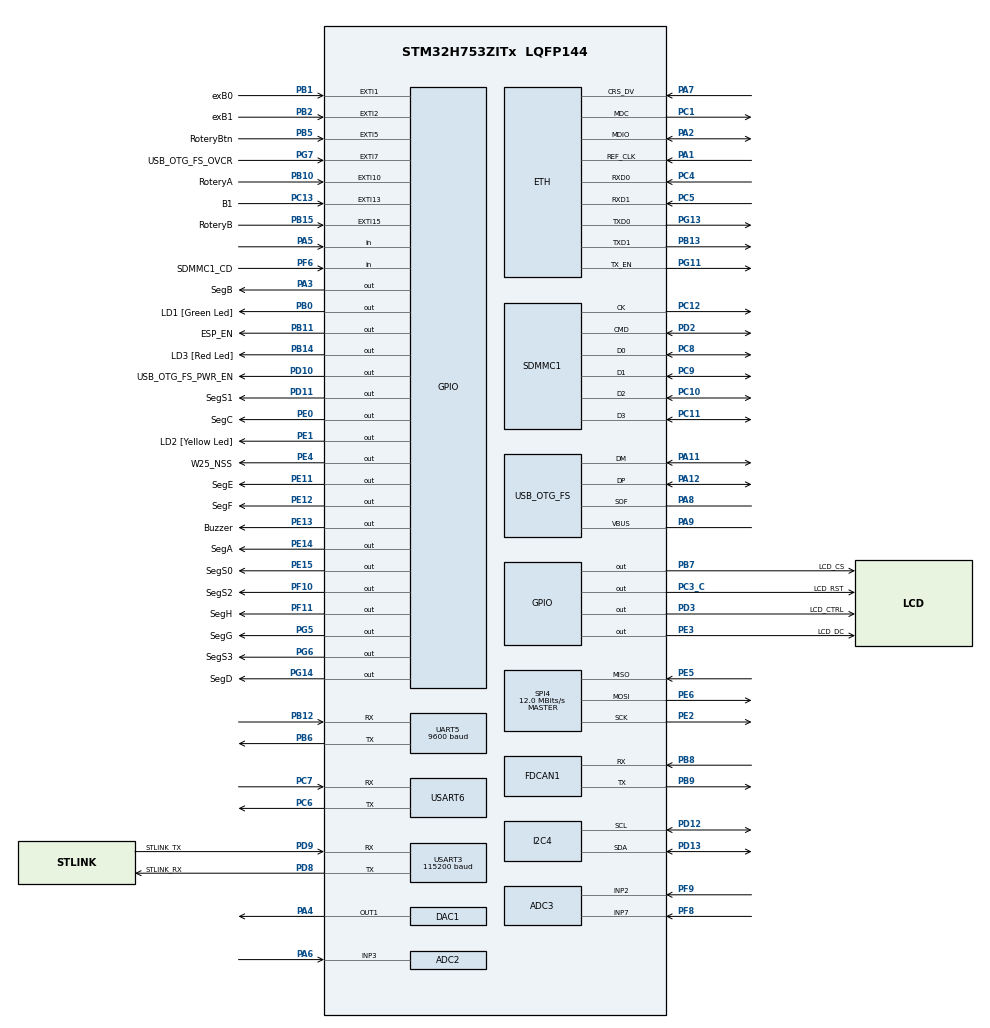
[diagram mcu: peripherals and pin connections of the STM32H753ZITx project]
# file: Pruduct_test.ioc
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ADC2.Channel-0\#ChannelRegularConversion=ADC_CHANNEL_3
ADC2.ClockPrescaler=ADC_CLOCK_ASYNC_DIV4
ADC2.ExternalTrigConv=ADC_EXTERNALTRIG_T15_TRGO
ADC2.NbrOfConversionFlag=1
ADC2.OffsetNumber-0\#ChannelRegularConversion=ADC_OFFSET_NONE
ADC2.OffsetSignedSaturation-0\#ChannelRegularConversion=DISABLE
ADC2.Rank-0\#ChannelRegularConversion=1
ADC2.SamplingTime-0\#ChannelRegularConversion=ADC_SAMPLETIME_387CYCLES_5
ADC3.Channel-0\#ChannelRegularConversion=ADC_CHANNEL_2
ADC3.NbrOfConversionFlag=1
ADC3.OffsetNumber-0\#ChannelRegularConversion=ADC_OFFSET_NONE
ADC3.OffsetSignedSaturation-0\#ChannelRegularConversion=DISABLE
ADC3.Rank-0\#ChannelRegularConversion=1
ADC3.SamplingTime-0\#ChannelRegularConversion=ADC_SAMPLETIME_1CYCLE_5
CORTEX_M7.AccessPermission-Cortex_Memory_Protection_Unit_Region1_Settings=MPU_REGION_FULL_ACCESS
CORTEX_M7.AccessPermission_S-Cortex_Memory_Protection_Unit_Region1_Settings_S=MPU_REGION_FULL_ACCESS
CORTEX_M7.AccessPermission_Spec=MPU_REGION_FULL_ACCESS
CORTEX_M7.BaseAddress-Cortex_Memory_Protection_Unit_Region0_Settings=0x0
CORTEX_M7.BaseAddress-Cortex_Memory_Protection_Unit_Region1_Settings=0x030020000
CORTEX_M7.BaseAddress-Cortex_Memory_Protection_Unit_Region2_Settings=0x30040000
CORTEX_M7.BaseAddress_S-Cortex_Memory_Protection_Unit_Region1_Settings_S=0x30040000
CORTEX_M7.BaseAddress_Spec=0x30020000
CORTEX_M7.CPU_DCache=Enabled
CORTEX_M7.CPU_ICache=Enabled
CORTEX_M7.DisableExec-Cortex_Memory_Protection_Unit_Region0_Settings=MPU_INSTRUCTION_ACCESS_DISABLE
CORTEX_M7.DisableExec_S-Cortex_Memory_Protection_Unit_Region1_Settings_S=MPU_INSTRUCTION_ACCESS_DISABLE
CORTEX_M7.DisableExec_Spec=MPU_INSTRUCTION_ACCESS_DISABLE
CORTEX_M7.Enable-Cortex_Memory_Protection_Unit_Region0_Settings=MPU_REGION_ENABLE
CORTEX_M7.Enable-Cortex_Memory_Protection_Unit_Region1_Settings=MPU_REGION_ENABLE
CORTEX_M7.Enable-Cortex_Memory_Protection_Unit_Region2_Settings=MPU_REGION_ENABLE
CORTEX_M7.Enable_S-Cortex_Memory_Protection_Unit_Region1_Settings_S=MPU_REGION_ENABLE
CORTEX_M7.Enable_S-Cortex_Memory_Protection_Unit_Region2_Settings_S=__NULL
CORTEX_M7.Enable_Spec=MPU_REGION_ENABLE
CORTEX_M7.IsBufferable-Cortex_Memory_Protection_Unit_Region0_Settings=MPU_ACCESS_NOT_BUFFERABLE
CORTEX_M7.IsBufferable-Cortex_Memory_Protection_Unit_Region1_Settings=MPU_ACCESS_BUFFERABLE
CORTEX_M7.IsBufferable-Cortex_Memory_Protection_Unit_Region2_Settings=MPU_ACCESS_BUFFERABLE
CORTEX_M7.IsBufferable_S-Cortex_Memory_Protection_Unit_Region1_Settings_S=MPU_ACCESS_BUFFERABLE
CORTEX_M7.IsBufferable_Spec=MPU_ACCESS_NOT_BUFFERABLE
CORTEX_M7.IsCacheable-Cortex_Memory_Protection_Unit_Region0_Settings=MPU_ACCESS_CACHEABLE
CORTEX_M7.IsCacheable-Cortex_Memory_Protection_Unit_Region1_Settings=MPU_ACCESS_CACHEABLE
CORTEX_M7.IsCacheable-Cortex_Memory_Protection_Unit_Region2_Settings=MPU_ACCESS_NOT_CACHEABLE
CORTEX_M7.IsCacheable_S-Cortex_Memory_Protection_Unit_Region1_Settings_S=MPU_ACCESS_NOT_CACHEABLE
CORTEX_M7.IsShareable-Cortex_Memory_Protection_Unit_Region0_Settings=MPU_ACCESS_SHAREABLE
CORTEX_M7.IsShareable-Cortex_Memory_Protection_Unit_Region2_Settings=MPU_ACCESS_SHAREABLE
CORTEX_M7.IsShareable_S-Cortex_Memory_Protection_Unit_Region1_Settings_S=MPU_ACCESS_SHAREABLE
CORTEX_M7.IsShareable_Spec=MPU_ACCESS_NOT_SHAREABLE
CORTEX_M7.MPU_Control=MPU_PRIVILEGED_DEFAULT
CORTEX_M7.Size-Cortex_Memory_Protection_Unit_Region0_Settings=MPU_REGION_SIZE_4GB
CORTEX_M7.Size-Cortex_Memory_Protection_Unit_Region1_Settings=MPU_REGION_SIZE_128KB
CORTEX_M7.Size-Cortex_Memory_Protection_Unit_Region2_Settings=MPU_REGION_SIZE_512B
CORTEX_M7.Size_S-Cortex_Memory_Protection_Unit_Region1_Settings_S=MPU_REGION_SIZE_512B
CORTEX_M7.Size_Spec=MPU_REGION_SIZE_128KB
CORTEX_M7.SubRegionDisable-Cortex_Memory_Protection_Unit_Region0_Settings=0x87
CORTEX_M7.SubRegionDisable_Spec=0x0
CORTEX_M7.TypeExtField-Cortex_Memory_Protection_Unit_Region1_Settings=MPU_TEX_LEVEL1
CORTEX_M7.TypeExtField_Spec=MPU_TEX_LEVEL1
CORTEX_M7.default_mode_Activation=1
DAC1.DAC_Channel-DAC_OUT1=DAC_CHANNEL_1
ETH.MACAddr=00\:80\:E1\:00\:00\:0D
ETH.MediaInterface=HAL_ETH_RMII_MODE
ETH.RxBuffLen=1536
ETH.RxBufferAddress=0x30040260
ETH.RxDescAddress=0x30040000
ETH.TxDescAddress=0x30040200
FATFS.BSP.number=1
FATFS0.BSP.STBoard=false
FATFS0.BSP.api=Unknown
FATFS0.BSP.instance=PF6
FATFS0.BSP.ip=GPIO
FATFS0.BSP.mode=Input
FATFS0.BSP.name=Detect_SDIO
FATFS0.BSP.solution=PF6
FDCAN1.AutoRetransmission=ENABLE
FDCAN1.CalculateBaudRateNominal=533333
FDCAN1.CalculateTimeBitNominal=1875
FDCAN1.CalculateTimeQuantumNominal=93.75
FDCAN1.DataPrescaler=5
FDCAN1.DataSyncJumpWidth=12
FDCAN1.DataTimeSeg1=4
FDCAN1.DataTimeSeg2=5
FDCAN1.FrameFormat=FDCAN_FRAME_FD_BRS
FDCAN1.NominalPrescaler=6
FDCAN1.NominalSyncJumpWidth=13
FDCAN1.NominalTimeSeg1=13
FDCAN1.NominalTimeSeg2=6
FDCAN1.RxBuffersNbr=1
FDCAN1.StdFiltersNbr=1
FDCAN1.TxBuffersNbr=1
I2C4.Timing=0x00000E14
LWIP.BSP.number=1
LWIP.GATEWAY_ADDRESS=192.168.000.001
LWIP.IP_ADDRESS=192.168.000.010
LWIP.LWIP_DBG_MIN_LEVEL=LWIP_DBG_MASK_LEVEL
LWIP.LWIP_DHCP=0
LWIP.LWIP_RAM_HEAP_POINTER=0x30020000
LWIP.MEM_SIZE=131048
LWIP.NETMASK_ADDRESS=255.255.255.000
LWIP.Version=v2.1.2_Cube
LWIP0.BSP.STBoard=false
LWIP0.BSP.api=BSP_COMPONENT_DRIVER
LWIP0.BSP.component=LAN8742
LWIP0.BSP.instance=LAN8742
LWIP0.BSP.name=Driver_PHY
LWIP0.BSP.semaphore=S_LAN8742
LWIP0.BSP.solution=LAN8742
Mcu.Family=STM32H7
Mcu.Name=STM32H753ZITx
Mcu.Package=LQFP144
NVIC.ADC_IRQn=true\:0\:0\:false\:false\:true\:true\:true\:true
NVIC.ETH_IRQn=true\:0\:0\:false\:false\:true\:true\:true\:true
NVIC.EXTI15_10_IRQn=true\:0\:0\:false\:false\:true\:true\:true\:true
NVIC.EXTI1_IRQn=true\:0\:0\:false\:false\:true\:true\:true\:true
NVIC.EXTI2_IRQn=true\:0\:0\:false\:false\:true\:true\:true\:true
NVIC.EXTI9_5_IRQn=true\:0\:0\:false\:false\:true\:true\:true\:true
NVIC.FDCAN1_IT0_IRQn=true\:0\:0\:false\:false\:true\:true\:true\:true
NVIC.OTG_FS_IRQn=true\:0\:0\:false\:false\:true\:false\:true\:true
NVIC.PriorityGroup=NVIC_PRIORITYGROUP_4
NVIC.TIM6_DAC_IRQn=true\:0\:0\:false\:false\:true\:true\:true\:true
NVIC.TIM7_IRQn=true\:0\:0\:false\:false\:true\:true\:true\:true
NVIC.USART6_IRQn=true\:0\:0\:false\:false\:true\:true\:true\:true
PA1.Mode=RMII
PA1.Signal=ETH_REF_CLK
PA11.Mode=Device_Only
PA11.Signal=USB_OTG_FS_DM
PA12.Mode=Device_Only
PA12.Signal=USB_OTG_FS_DP
PA2.Mode=RMII
PA2.Signal=ETH_MDIO
PA3.GPIO_Label=SegB
PA3.Signal=GPIO_Output
PA4.Signal=COMP_DAC11_group
PA5.Signal=GPIO_Input
PA6.Signal=ADCx_INP3
PA7.Mode=RMII
PA7.Signal=ETH_CRS_DV
PA8.Mode=Activate_SOF_FS
PA8.PinAttribute=Free
PA8.Signal=USB_OTG_FS_SOF
PA9.Mode=Activate_VBUS
PA9.PinAttribute=Free
PA9.Signal=USB_OTG_FS_VBUS
PB0.GPIO_Label=LD1 [Green Led]
PB0.Signal=GPIO_Output
PB1.GPIO_Label=exB0
PB1.Signal=GPXTI1
PB10.GPIO_Label=RoteryA
PB10.PinAttribute=Free
PB10.Signal=GPXTI10
PB11.GPIO_Label=ESP_EN
PB11.Signal=GPIO_Output
PB12.Mode=Asynchronous
PB12.Signal=UART5_RX
PB13.Mode=RMII
PB13.Signal=ETH_TXD1
PB14.GPIO_Label=LD3 [Red Led]
PB14.Signal=GPIO_Output
PB15.GPIO_Label=RoteryB
PB15.Signal=GPXTI15
PB2.GPIO_Label=exB1
PB2.PinAttribute=Free
PB2.Signal=GPXTI2
PB5.GPIO_Label=RoteryBtn
PB5.Signal=GPXTI5
PB6.Mode=Asynchronous
PB6.Signal=UART5_TX
PB7.GPIO_Label=LCD_CS
PB7.GPIO_Speed=GPIO_SPEED_FREQ_HIGH
PB7.Signal=GPIO_Output
PB8.Mode=FDCAN_Activate
PB8.Signal=FDCAN1_RX
PB9.Mode=FDCAN_Activate
PB9.Signal=FDCAN1_TX
PC1.Mode=RMII
PC1.Signal=ETH_MDC
PC10.Mode=SD_4_bits_Wide_bus
PC10.Signal=SDMMC1_D2
PC11.Mode=SD_4_bits_Wide_bus
PC11.Signal=SDMMC1_D3
PC12.Mode=SD_4_bits_Wide_bus
PC12.Signal=SDMMC1_CK
PC13.GPIO_Label=B1
PC13.Signal=GPXTI13
PC14-OSC32_IN\ (OSC32_IN).Mode=LSE-External-Oscillator
PC14-OSC32_IN\ (OSC32_IN).Signal=RCC_OSC32_IN
PC15-OSC32_OUT\ (OSC32_OUT).Mode=LSE-External-Oscillator
PC15-OSC32_OUT\ (OSC32_OUT).Signal=RCC_OSC32_OUT
PC3_C.GPIO_Label=LCD_RST
PC3_C.Signal=GPIO_Output
PC4.Mode=RMII
PC4.PinAttribute=Free
PC4.Signal=ETH_RXD0
PC5.Mode=RMII
PC5.PinAttribute=Free
PC5.Signal=ETH_RXD1
PC6.Mode=Asynchronous
PC6.Signal=USART6_TX
PC7.Mode=Asynchronous
PC7.Signal=USART6_RX
PC8.Mode=SD_4_bits_Wide_bus
PC8.Signal=SDMMC1_D0
PC9.Mode=SD_4_bits_Wide_bus
PC9.Signal=SDMMC1_D1
PD10.GPIO_Label=USB_OTG_FS_PWR_EN
PD10.Signal=GPIO_Output
PD11.GPIO_Label=SegS1
PD11.PinAttribute=Free
PD11.Signal=GPIO_Output
PD12.Mode=I2C
PD12.Signal=I2C4_SCL
PD13.Mode=I2C
PD13.Signal=I2C4_SDA
PD2.Mode=SD_4_bits_Wide_bus
PD2.Signal=SDMMC1_CMD
PD3.GPIO_Label=LCD_CTRL
PD3.Signal=GPIO_Output
PD8.GPIO_Label=STLINK_RX
PD8.Mode=Asynchronous
PD8.Signal=USART3_TX
PD9.GPIO_Label=STLINK_TX
PD9.Mode=Asynchronous
PD9.Signal=USART3_RX
PE0.GPIO_Label=SegC
PE0.Signal=GPIO_Output
PE1.GPIO_Label=LD2 [Yellow Led]
PE1.Signal=GPIO_Output
PE11.GPIO_Label=SegE
PE11.Signal=GPIO_Output
PE12.GPIO_Label=SegF
PE12.Signal=GPIO_Output
PE13.GPIO_Label=Buzzer
PE13.Signal=GPIO_Output
PE14.GPIO_Label=SegA
PE14.Signal=GPIO_Output
PE15.GPIO_Label=SegS0
PE15.Signal=GPIO_Output
PE2.Mode=Full_Duplex_Master
PE2.PinAttribute=Free
PE2.Signal=SPI4_SCK
PE3.GPIO_Label=LCD_DC
PE3.GPIO_Speed=GPIO_SPEED_FREQ_HIGH
PE3.PinAttribute=Free
PE3.Signal=GPIO_Output
PE4.GPIO_Label=W25_NSS
PE4.GPIO_PuPd=GPIO_PULLUP
PE4.GPIO_Speed=GPIO_SPEED_FREQ_HIGH
PE4.PinAttribute=Free
PE4.PinState=GPIO_PIN_SET
PE4.Signal=GPIO_Output
PE5.Mode=Full_Duplex_Master
PE5.PinAttribute=Free
PE5.Signal=SPI4_MISO
PE6.Mode=Full_Duplex_Master
PE6.Signal=SPI4_MOSI
PF10.GPIO_Label=SegS2
PF10.Signal=GPIO_Output
PF11.GPIO_Label=SegH
PF11.Signal=GPIO_Output
PF6.GPIO_Label=SDMMC1_CD
PF6.Signal=GPIO_Input
PF8.Mode=IN7-Single-Ended
PF8.Signal=ADC3_INP7
PF9.Mode=IN2-Single-Ended
PF9.Signal=ADC3_INP2
PG11.Mode=RMII
PG11.Signal=ETH_TX_EN
PG13.Mode=RMII
PG13.Signal=ETH_TXD0
PG14.GPIO_Label=SegD
PG14.Signal=GPIO_Output
PG5.GPIO_Label=SegG
PG5.Signal=GPIO_Output
PG6.GPIO_Label=SegS3
PG6.Signal=GPIO_Output
PG7.GPIO_Label=USB_OTG_FS_OVCR
PG7.Signal=GPXTI7
PH0-OSC_IN\ (PH0).Mode=HSE-External-Clock-Source
PH0-OSC_IN\ (PH0).Signal=RCC_OSC_IN
PH1-OSC_OUT\ (PH1).Signal=RCC_OSC_OUT
ProjectManager.HeapSize=0x200
ProjectManager.StackSize=0x400
ProjectManager.TargetToolchain=STM32CubeIDE
RCC.ADCCLockSelection=RCC_ADCCLKSOURCE_CLKP
RCC.ADCFreq_Value=64000000
RCC.APB1Freq_Value=24000000
RCC.APB2Freq_Value=24000000
RCC.APB3Freq_Value=48000000
RCC.APB4Freq_Value=48000000
RCC.CortexFreq_Value=96000000
RCC.D2PPRE1=RCC_APB1_DIV2
RCC.D2PPRE2=RCC_APB2_DIV2
RCC.DIVM1=4
RCC.DIVM2=25
RCC.DIVM3=60
RCC.DIVN1=12
RCC.DIVN2=95
RCC.DIVP2=100
RCC.DIVQ1=3
RCC.DIVQ2=4
RCC.DIVR2=121
RCC.FDCANCLockSelection=RCC_FDCANCLKSOURCE_PLL2
RCC.HCLKFreq_Value=48000000
RCC.HPRE=RCC_HCLK_DIV2
RCC.HSE_VALUE=8000000
RCC.I2C4CLockSelection=RCC_I2C4CLKSOURCE_CSI
RCC.MCO2OutPutEnable-ClockTree=true
RCC.PLL1_VCI_Range-AdvancedSettings=RCC_PLL1VCIRANGE_0
RCC.PLL1_VCO_SEL-AdvancedSettings=RCC_PLL1VCOMEDIUM
RCC.PLL2FRACN=0
RCC.PLL2_VCO_SEL-AdvancedSettings=RCC_PLL2VCOMEDIUM
RCC.PLL3FRACN=0
RCC.PLL3_VCO_SEL-AdvancedSettings=RCC_PLL3VCOMEDIUM
RCC.PLLFRACN=0
RCC.QuadSPIEnable-ClockTree=true
RCC.SAI23Enable-ClockTree=true
RCC.SDMMC1CLockSelection=RCC_SDMMCCLKSOURCE_PLL2
RCC.SYSCLKFreq_VALUE=96000000
RCC.SYSCLKSource=RCC_SYSCLKSOURCE_PLLCLK
RCC.USBCLockSelection=RCC_USBCLKSOURCE_HSI48
RCC.USBFreq_Value=48000000
SH.ADCx_INP3.0=ADC2_INP3,IN3-Single-Ended
SH.COMP_DAC11_group.0=DAC1_OUT1,DAC_OUT1
SPI4.BaudRatePrescaler=SPI_BAUDRATEPRESCALER_2
SPI4.CalculateBaudRate=12.0 MBits/s
SPI4.DataSize=SPI_DATASIZE_16BIT
SPI4.Direction=SPI_DIRECTION_2LINES
SPI4.Mode=SPI_MODE_MASTER
SPI4.VirtualType=VM_MASTER
TIM15.AutoReloadPreload=TIM_AUTORELOAD_PRELOAD_ENABLE
TIM15.Period=1000
TIM15.Prescaler=48000
TIM15.TIM_MasterOutputTrigger=TIM_TRGO_UPDATE
TIM6.AutoReloadPreload=TIM_AUTORELOAD_PRELOAD_ENABLE
TIM6.Period=4000
TIM6.Prescaler=120
TIM6.TIM_MasterOutputTrigger=TIM_TRGO_UPDATE
TIM7.AutoReloadPreload=TIM_AUTORELOAD_PRELOAD_ENABLE
TIM7.Period=1000
TIM7.Prescaler=12000
TIM7.TIM_MasterOutputTrigger=TIM_TRGO_UPDATE
UART5.BaudRate=9600
USART3.AutoBaudRateEnableParam=UART_ADVFEATURE_AUTOBAUDRATE_DISABLE
USART3.BaudRate=115200
USART3.ClockPrescaler=PRESCALER_DIV1
USART3.DMADisableonRxErrorParam=ADVFEATURE_DMA_ENABLEONRXERROR
USART3.DataInvertParam=ADVFEATURE_DATAINV_DISABLE
USART3.FIFOMode=FIFOMODE_DISABLE
USART3.MSBFirstParam=ADVFEATURE_MSBFIRST_DISABLE
USART3.Mode=MODE_TX_RX
USART3.OneBitSampling=UART_ONE_BIT_SAMPLE_DISABLE
USART3.OverSampling=UART_OVERSAMPLING_16
USART3.OverrunDisableParam=ADVFEATURE_OVERRUN_ENABLE
USART3.Parity=PARITY_NONE
USART3.RXFIFOThreshold=RXFIFO_THRESHOLD_1EIGHTHFULL
USART3.RxPinLevelInvertParam=ADVFEATURE_RXINV_DISABLE
USART3.StopBits=STOPBITS_1
USART3.SwapParam=ADVFEATURE_SWAP_DISABLE
USART3.TXFIFOThreshold=TXFIFO_THRESHOLD_1EIGHTHFULL
USART3.TxPinLevelInvertParam=ADVFEATURE_TXINV_DISABLE
USART3.VirtualMode-Asynchronous=VM_ASYNC
USART3.WordLength=WORDLENGTH_8B
USART6.VirtualMode-Asynchronous=VM_ASYNC
USB_DEVICE.CLASS_NAME_FS=CDC
USB_DEVICE.VirtualMode-CDC_FS=Cdc
USB_DEVICE.VirtualModeFS=Cdc_FS
USB_OTG_FS.Sof_enable=ENABLE
USB_OTG_FS.VirtualMode=Device_Only
USB_OTG_FS.battery_charging_enable=ENABLE
USB_OTG_FS.low_power_enable=DISABLE
USB_OTG_FS.lpm_enable=DISABLE
USB_OTG_FS.use_dedicated_ep1=DISABLE
USB_OTG_FS.vbus_sensing_enable=ENABLE
VP_FATFS_VS_SDIO.Mode=SDIO
VP_LWIP_VS_Enabled.Mode=Enabled
VP_MEMORYMAP_VS_MEMORYMAP.Mode=CurAppReg
VP_TIM15_VS_ClockSourceINT.Mode=Internal
VP_TIM6_VS_ClockSourceINT.Mode=Enable_Timer
VP_TIM7_VS_ClockSourceINT.Mode=Enable_Timer
VP_USB_DEVICE_VS_USB_DEVICE_CDC_FS.Mode=CDC_FS
board=NUCLEO-H753ZI

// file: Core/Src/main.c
/* USER CODE BEGIN Header */
/**
 ******************************************************************************
 * @file           : main.c
 * @brief          : Main program body
 ******************************************************************************
 * @attention
 *
 * Copyright (c) 2024 STMicroelectronics.
 * All rights reserved.
 *
 * This software is licensed under terms that can be found in the LICENSE file
 * in the root directory of this software component.
 * If no LICENSE file comes with this software, it is provided AS-IS.
 *
 ******************************************************************************
 */
/* USER CODE END Header */
#include "main.h"
#include "fatfs.h"
#include "lwip.h"
#include "usb_device.h"

/* USER CODE BEGIN Includes */
#include "text_panel.h"
#include "test_case.h"
#include "segment.h"
#include "rotary.h"
#include "SSD1289.h"
#include "lcd_touch.h"
/* USER CODE END Includes */

ADC_HandleTypeDef hadc2;
ADC_HandleTypeDef hadc3;

DAC_HandleTypeDef hdac1;

FDCAN_HandleTypeDef hfdcan1;

I2C_HandleTypeDef hi2c4;

SD_HandleTypeDef hsd1;

SPI_HandleTypeDef hspi4;

TIM_HandleTypeDef htim6;
TIM_HandleTypeDef htim7;
TIM_HandleTypeDef htim15;

UART_HandleTypeDef huart5;
UART_HandleTypeDef huart3;
UART_HandleTypeDef huart6;

/* USER CODE BEGIN PV */
ADC_HandleTypeDef hadc3;
static segment_t *seg_handle = NULL;

uint16_t x;
uint16_t y;
uint16_t last_x, last_y;
uint16_t buf[320];
extern SSD1289_handle handle;
SSD1289_handle *lcd = &handle;

FDCAN_RxHeaderTypeDef RxHeader;
uint8_t RxData[2];
FDCAN_TxHeaderTypeDef TxHeader;
uint8_t TxData[2] = { 1, 0x10 };
/* USER CODE END PV */

void SystemClock_Config(void);
void PeriphCommonClock_Config(void);
static void MPU_Config(void);
static void MX_GPIO_Init(void);
static void MX_USART3_UART_Init(void);
static void MX_SPI4_Init(void);
static void MX_I2C4_Init(void);
static void MX_TIM6_Init(void);
static void MX_ADC2_Init(void);
static void MX_TIM15_Init(void);
static void MX_DAC1_Init(void);
static void MX_USART6_UART_Init(void);
static void MX_UART5_Init(void);
static void MX_SDMMC1_SD_Init(void);
static void MX_TIM7_Init(void);
static void MX_FDCAN1_Init(void);
static void MX_ADC3_Init(void);
/* USER CODE BEGIN PFP */
void invoke_case(const char *case_name, bool (*fn)());
void touch_event();
static void FDCAN_Config(void);
/* USER CODE END PFP */

/* USER CODE BEGIN 0 */
extern struct netif gnetif;
/* USER CODE END 0 */

int main(void)
{

  /* MPU Configuration--------------------------------------------------------*/
  MPU_Config();

  /* Enable the CPU Cache */

  /* Enable I-Cache---------------------------------------------------------*/
  SCB_EnableICache();

  /* Enable D-Cache---------------------------------------------------------*/
  SCB_EnableDCache();

  /* MCU Configuration--------------------------------------------------------*/

  /* Reset of all peripherals, Initializes the Flash interface and the Systick. */
  HAL_Init();

  /* Configure the system clock */
  SystemClock_Config();

  /* Configure the peripherals common clocks */
  PeriphCommonClock_Config();

  /* Initialize all configured peripherals */
  MX_GPIO_Init();
  MX_USART3_UART_Init();
  MX_USB_DEVICE_Init();
  MX_SPI4_Init();
  MX_I2C4_Init();
  MX_TIM6_Init();
  MX_ADC2_Init();
  MX_TIM15_Init();
  MX_DAC1_Init();
  MX_USART6_UART_Init();
  MX_UART5_Init();
  MX_SDMMC1_SD_Init();
  MX_FATFS_Init();
  MX_TIM7_Init();
  MX_FDCAN1_Init();
  MX_ADC3_Init();
  MX_LWIP_Init();
  /* USER CODE BEGIN 2 */
	FDCAN_Config();

	test_case_init();
	text_panel_init();

	text_panel_print("Buzzer Start 1s.\n");
	int b_start = HAL_GetTick();
	while(HAL_GetTick() - b_start < 1000) {
		HAL_GPIO_TogglePin(Buzzer_GPIO_Port, Buzzer_Pin);
		HAL_Delay(1);
	}

	seg_handle = segment_new(4);
	if (seg_handle != NULL) {
		segment_num_set(seg_handle, 0);
		HAL_TIM_Base_Start_IT(&htim6);
		HAL_TIM_Base_Start(&htim15);
		HAL_ADC_Start_IT(&hadc2);
		HAL_DAC_SetValue(&hdac1, DAC_CHANNEL_1, DAC_ALIGN_12B_R, 0);
		HAL_DAC_Start(&hdac1, DAC_CHANNEL_1);
	} else {
		text_panel_print("Memory error.\n");
		Error_Handler();
	}

	text_panel_print("Product Test start...\n");

	MX_USB_DEVICE_Init();
	text_panel_print("Usb Comport enabled.\n");
	HAL_TIM_Base_Start_IT(&htim7);

	invoke_case("I2C", test_case_i2c);
	invoke_case("Rs232", test_case_rs232);
	text_panel_print("CAN test...");
	HAL_FDCAN_AddMessageToTxBuffer(&hfdcan1, &TxHeader, TxData,
	FDCAN_TX_BUFFER0);
	if (HAL_FDCAN_EnableTxBufferRequest(&hfdcan1, FDCAN_TX_BUFFER0) != HAL_OK) {
		text_panel_print(" Eanble Tx fail\n");
	} else {
		uint32_t start = HAL_GetTick();
		while (HAL_FDCAN_IsTxBufferMessagePending(&hfdcan1,
		FDCAN_TX_BUFFER0) == 1 && HAL_GetTick() - start <= 1000)
			;;
		if (HAL_GetTick() - start >= 1000) {
			text_panel_print("Fail\n");
		} else {
			text_panel_print("Ok\n");
		}
	}
	invoke_case("W25", test_case_spi);
	invoke_case("SDIO", test_case_SDIO);
	invoke_case("AI-WB2", test_case_WV2);
	invoke_case("Button", test_case_button);
	invoke_case("Rotery", test_case_rotery);

	LCD_Touch_Init(&hadc3, LCD_XM_ADC_CH, LCD_YP_ADC_CH);
	text_panel_print("LCD touch Service start.\n");

	text_panel_print("Ethernet Service start.\n");
	text_panel_print("IP: 192.168.0.10\nMASK: 255.255.255.0\nMAC: 00:80:E1:00:0D\n");
	text_panel_print("Fin\n");
  /* USER CODE END 2 */

  /* Infinite loop */
	while (1) {

    /* USER CODE BEGIN 3 */

		touch_event();

		HAL_Delay(100);
	}
  /* USER CODE END 3 */
}

void SystemClock_Config(void)
{
  RCC_OscInitTypeDef RCC_OscInitStruct = {0};
  RCC_ClkInitTypeDef RCC_ClkInitStruct = {0};

  /** Supply configuration update enable
  */
  HAL_PWREx_ConfigSupply(PWR_LDO_SUPPLY);

  /** Configure the main internal regulator output voltage
  */
  __HAL_PWR_VOLTAGESCALING_CONFIG(PWR_REGULATOR_VOLTAGE_SCALE3);

  while(!__HAL_PWR_GET_FLAG(PWR_FLAG_VOSRDY)) {}

  /** Initializes the RCC Oscillators according to the specified parameters
  * in the RCC_OscInitTypeDef structure.
  */
  RCC_OscInitStruct.OscillatorType = RCC_OSCILLATORTYPE_HSI48|RCC_OSCILLATORTYPE_CSI
                              |RCC_OSCILLATORTYPE_HSI;
  RCC_OscInitStruct.HSIState = RCC_HSI_DIV1;
  RCC_OscInitStruct.HSICalibrationValue = RCC_HSICALIBRATION_DEFAULT;
  RCC_OscInitStruct.HSI48State = RCC_HSI48_ON;
  RCC_OscInitStruct.CSIState = RCC_CSI_ON;
  RCC_OscInitStruct.CSICalibrationValue = RCC_CSICALIBRATION_DEFAULT;
  RCC_OscInitStruct.PLL.PLLState = RCC_PLL_ON;
  RCC_OscInitStruct.PLL.PLLSource = RCC_PLLSOURCE_HSI;
  RCC_OscInitStruct.PLL.PLLM = 4;
  RCC_OscInitStruct.PLL.PLLN = 12;
  RCC_OscInitStruct.PLL.PLLP = 2;
  RCC_OscInitStruct.PLL.PLLQ = 3;
  RCC_OscInitStruct.PLL.PLLR = 2;
  RCC_OscInitStruct.PLL.PLLRGE = RCC_PLL1VCIRANGE_3;
  RCC_OscInitStruct.PLL.PLLVCOSEL = RCC_PLL1VCOMEDIUM;
  RCC_OscInitStruct.PLL.PLLFRACN = 0;
  if (HAL_RCC_OscConfig(&RCC_OscInitStruct) != HAL_OK)
  {
    Error_Handler();
  }

  /** Initializes the CPU, AHB and APB buses clocks
  */
  RCC_ClkInitStruct.ClockType = RCC_CLOCKTYPE_HCLK|RCC_CLOCKTYPE_SYSCLK
                              |RCC_CLOCKTYPE_PCLK1|RCC_CLOCKTYPE_PCLK2
                              |RCC_CLOCKTYPE_D3PCLK1|RCC_CLOCKTYPE_D1PCLK1;
  RCC_ClkInitStruct.SYSCLKSource = RCC_SYSCLKSOURCE_PLLCLK;
  RCC_ClkInitStruct.SYSCLKDivider = RCC_SYSCLK_DIV1;
  RCC_ClkInitStruct.AHBCLKDivider = RCC_HCLK_DIV2;
  RCC_ClkInitStruct.APB3CLKDivider = RCC_APB3_DIV1;
  RCC_ClkInitStruct.APB1CLKDivider = RCC_APB1_DIV2;
  RCC_ClkInitStruct.APB2CLKDivider = RCC_APB2_DIV2;
  RCC_ClkInitStruct.APB4CLKDivider = RCC_APB4_DIV1;

  if (HAL_RCC_ClockConfig(&RCC_ClkInitStruct, FLASH_LATENCY_1) != HAL_OK)
  {
    Error_Handler();
  }
}

void PeriphCommonClock_Config(void)
{
  RCC_PeriphCLKInitTypeDef PeriphClkInitStruct = {0};

  /** Initializes the peripherals clock
  */
  PeriphClkInitStruct.PeriphClockSelection = RCC_PERIPHCLK_SDMMC|RCC_PERIPHCLK_FDCAN
                              |RCC_PERIPHCLK_CKPER;
  PeriphClkInitStruct.PLL2.PLL2M = 25;
  PeriphClkInitStruct.PLL2.PLL2N = 95;
  PeriphClkInitStruct.PLL2.PLL2P = 100;
  PeriphClkInitStruct.PLL2.PLL2Q = 4;
  PeriphClkInitStruct.PLL2.PLL2R = 121;
  PeriphClkInitStruct.PLL2.PLL2RGE = RCC_PLL2VCIRANGE_1;
  PeriphClkInitStruct.PLL2.PLL2VCOSEL = RCC_PLL2VCOMEDIUM;
  PeriphClkInitStruct.PLL2.PLL2FRACN = 0;
  PeriphClkInitStruct.SdmmcClockSelection = RCC_SDMMCCLKSOURCE_PLL2;
  PeriphClkInitStruct.CkperClockSelection = RCC_CLKPSOURCE_HSI;
  PeriphClkInitStruct.FdcanClockSelection = RCC_FDCANCLKSOURCE_PLL2;
  if (HAL_RCCEx_PeriphCLKConfig(&PeriphClkInitStruct) != HAL_OK)
  {
    Error_Handler();
  }
}

static void MX_ADC2_Init(void)
{

  ADC_ChannelConfTypeDef sConfig = {0};

  /** Common config
  */
  hadc2.Instance = ADC2;
  hadc2.Init.ScanConvMode = ADC_SCAN_DISABLE;
  hadc2.Init.EOCSelection = ADC_EOC_SINGLE_CONV;
  hadc2.Init.LowPowerAutoWait = DISABLE;
  hadc2.Init.ContinuousConvMode = DISABLE;
  hadc2.Init.NbrOfConversion = 1;
  hadc2.Init.DiscontinuousConvMode = DISABLE;
  hadc2.Init.ExternalTrigConv = ADC_EXTERNALTRIG_T15_TRGO;
  hadc2.Init.ExternalTrigConvEdge = ADC_EXTERNALTRIGCONVEDGE_RISING;
  hadc2.Init.ConversionDataManagement = ADC_CONVERSIONDATA_DR;
  hadc2.Init.Overrun = ADC_OVR_DATA_PRESERVED;
  hadc2.Init.LeftBitShift = ADC_LEFTBITSHIFT_NONE;
  hadc2.Init.OversamplingMode = DISABLE;
  hadc2.Init.Oversampling.Ratio = 1;
  if (HAL_ADC_Init(&hadc2) != HAL_OK)
  {
    Error_Handler();
  }
  hadc2.Init.ClockPrescaler = ADC_CLOCK_ASYNC_DIV4;
  hadc2.Init.Resolution = ADC_RESOLUTION_16B;
  if (HAL_ADC_Init(&hadc2) != HAL_OK)
  {
    Error_Handler();
  }

  /** Configure Regular Channel
  */
  sConfig.Channel = ADC_CHANNEL_3;
  sConfig.Rank = ADC_REGULAR_RANK_1;
  sConfig.SamplingTime = ADC_SAMPLETIME_387CYCLES_5;
  sConfig.SingleDiff = ADC_SINGLE_ENDED;
  sConfig.OffsetNumber = ADC_OFFSET_NONE;
  sConfig.Offset = 0;
  sConfig.OffsetSignedSaturation = DISABLE;
  if (HAL_ADC_ConfigChannel(&hadc2, &sConfig) != HAL_OK)
  {
    Error_Handler();
  }

}

static void MX_ADC3_Init(void)
{

  ADC_ChannelConfTypeDef sConfig = {0};

  /** Common config
  */
  hadc3.Instance = ADC3;
  hadc3.Init.ClockPrescaler = ADC_CLOCK_ASYNC_DIV1;
  hadc3.Init.ScanConvMode = ADC_SCAN_DISABLE;
  hadc3.Init.EOCSelection = ADC_EOC_SINGLE_CONV;
  hadc3.Init.LowPowerAutoWait = DISABLE;
  hadc3.Init.ContinuousConvMode = DISABLE;
  hadc3.Init.NbrOfConversion = 1;
  hadc3.Init.DiscontinuousConvMode = DISABLE;
  hadc3.Init.ExternalTrigConv = ADC_SOFTWARE_START;
  hadc3.Init.ExternalTrigConvEdge = ADC_EXTERNALTRIGCONVEDGE_NONE;
  hadc3.Init.ConversionDataManagement = ADC_CONVERSIONDATA_DR;
  hadc3.Init.Overrun = ADC_OVR_DATA_PRESERVED;
  hadc3.Init.LeftBitShift = ADC_LEFTBITSHIFT_NONE;
  hadc3.Init.OversamplingMode = DISABLE;
  hadc3.Init.Oversampling.Ratio = 1;
  if (HAL_ADC_Init(&hadc3) != HAL_OK)
  {
    Error_Handler();
  }
  hadc3.Init.Resolution = ADC_RESOLUTION_16B;
  if (HAL_ADC_Init(&hadc3) != HAL_OK)
  {
    Error_Handler();
  }

  /** Configure Regular Channel
  */
  sConfig.Channel = ADC_CHANNEL_2;
  sConfig.Rank = ADC_REGULAR_RANK_1;
  sConfig.SamplingTime = ADC_SAMPLETIME_1CYCLE_5;
  sConfig.SingleDiff = ADC_SINGLE_ENDED;
  sConfig.OffsetNumber = ADC_OFFSET_NONE;
  sConfig.Offset = 0;
  sConfig.OffsetSignedSaturation = DISABLE;
  if (HAL_ADC_ConfigChannel(&hadc3, &sConfig) != HAL_OK)
  {
    Error_Handler();
  }

}

static void MX_DAC1_Init(void)
{

  DAC_ChannelConfTypeDef sConfig = {0};

  /** DAC Initialization
  */
  hdac1.Instance = DAC1;
  if (HAL_DAC_Init(&hdac1) != HAL_OK)
  {
    Error_Handler();
  }

  /** DAC channel OUT1 config
  */
  sConfig.DAC_SampleAndHold = DAC_SAMPLEANDHOLD_DISABLE;
  sConfig.DAC_Trigger = DAC_TRIGGER_NONE;
  sConfig.DAC_OutputBuffer = DAC_OUTPUTBUFFER_ENABLE;
  sConfig.DAC_ConnectOnChipPeripheral = DAC_CHIPCONNECT_DISABLE;
  sConfig.DAC_UserTrimming = DAC_TRIMMING_FACTORY;
  if (HAL_DAC_ConfigChannel(&hdac1, &sConfig, DAC_CHANNEL_1) != HAL_OK)
  {
    Error_Handler();
  }

}

static void MX_FDCAN1_Init(void)
{

  hfdcan1.Instance = FDCAN1;
  hfdcan1.Init.FrameFormat = FDCAN_FRAME_FD_BRS;
  hfdcan1.Init.Mode = FDCAN_MODE_NORMAL;
  hfdcan1.Init.AutoRetransmission = ENABLE;
  hfdcan1.Init.TransmitPause = DISABLE;
  hfdcan1.Init.ProtocolException = DISABLE;
  hfdcan1.Init.NominalPrescaler = 6;
  hfdcan1.Init.NominalSyncJumpWidth = 13;
  hfdcan1.Init.NominalTimeSeg1 = 13;
  hfdcan1.Init.NominalTimeSeg2 = 6;
  hfdcan1.Init.DataPrescaler = 5;
  hfdcan1.Init.DataSyncJumpWidth = 12;
  hfdcan1.Init.DataTimeSeg1 = 4;
  hfdcan1.Init.DataTimeSeg2 = 5;
  hfdcan1.Init.MessageRAMOffset = 0;
  hfdcan1.Init.StdFiltersNbr = 1;
  hfdcan1.Init.ExtFiltersNbr = 0;
  hfdcan1.Init.RxFifo0ElmtsNbr = 0;
  hfdcan1.Init.RxFifo0ElmtSize = FDCAN_DATA_BYTES_8;
  hfdcan1.Init.RxFifo1ElmtsNbr = 0;
  hfdcan1.Init.RxFifo1ElmtSize = FDCAN_DATA_BYTES_8;
  hfdcan1.Init.RxBuffersNbr = 1;
  hfdcan1.Init.RxBufferSize = FDCAN_DATA_BYTES_8;
  hfdcan1.Init.TxEventsNbr = 0;
  hfdcan1.Init.TxBuffersNbr = 1;
  hfdcan1.Init.TxFifoQueueElmtsNbr = 0;
  hfdcan1.Init.TxFifoQueueMode = FDCAN_TX_FIFO_OPERATION;
  hfdcan1.Init.TxElmtSize = FDCAN_DATA_BYTES_8;
  if (HAL_FDCAN_Init(&hfdcan1) != HAL_OK)
  {
    Error_Handler();
  }

}

static void MX_I2C4_Init(void)
{

  hi2c4.Instance = I2C4;
  hi2c4.Init.Timing = 0x00000E14;
  hi2c4.Init.OwnAddress1 = 0;
  hi2c4.Init.AddressingMode = I2C_ADDRESSINGMODE_7BIT;
  hi2c4.Init.DualAddressMode = I2C_DUALADDRESS_DISABLE;
  hi2c4.Init.OwnAddress2 = 0;
  hi2c4.Init.OwnAddress2Masks = I2C_OA2_NOMASK;
  hi2c4.Init.GeneralCallMode = I2C_GENERALCALL_DISABLE;
  hi2c4.Init.NoStretchMode = I2C_NOSTRETCH_DISABLE;
  if (HAL_I2C_Init(&hi2c4) != HAL_OK)
  {
    Error_Handler();
  }

  /** Configure Analogue filter
  */
  if (HAL_I2CEx_ConfigAnalogFilter(&hi2c4, I2C_ANALOGFILTER_ENABLE) != HAL_OK)
  {
    Error_Handler();
  }

  /** Configure Digital filter
  */
  if (HAL_I2CEx_ConfigDigitalFilter(&hi2c4, 0) != HAL_OK)
  {
    Error_Handler();
  }

}

static void MX_SDMMC1_SD_Init(void)
{

  hsd1.Instance = SDMMC1;
  hsd1.Init.ClockEdge = SDMMC_CLOCK_EDGE_RISING;
  hsd1.Init.ClockPowerSave = SDMMC_CLOCK_POWER_SAVE_DISABLE;
  hsd1.Init.BusWide = SDMMC_BUS_WIDE_4B;
  hsd1.Init.HardwareFlowControl = SDMMC_HARDWARE_FLOW_CONTROL_DISABLE;
  hsd1.Init.ClockDiv = 0;

}

static void MX_SPI4_Init(void)
{

  /* SPI4 parameter configuration*/
  hspi4.Instance = SPI4;
  hspi4.Init.Mode = SPI_MODE_MASTER;
  hspi4.Init.Direction = SPI_DIRECTION_2LINES;
  hspi4.Init.DataSize = SPI_DATASIZE_16BIT;
  hspi4.Init.CLKPolarity = SPI_POLARITY_LOW;
  hspi4.Init.CLKPhase = SPI_PHASE_1EDGE;
  hspi4.Init.NSS = SPI_NSS_SOFT;
  hspi4.Init.BaudRatePrescaler = SPI_BAUDRATEPRESCALER_2;
  hspi4.Init.FirstBit = SPI_FIRSTBIT_MSB;
  hspi4.Init.TIMode = SPI_TIMODE_DISABLE;
  hspi4.Init.CRCCalculation = SPI_CRCCALCULATION_DISABLE;
  hspi4.Init.CRCPolynomial = 0x0;
  hspi4.Init.NSSPMode = SPI_NSS_PULSE_ENABLE;
  hspi4.Init.NSSPolarity = SPI_NSS_POLARITY_LOW;
  hspi4.Init.FifoThreshold = SPI_FIFO_THRESHOLD_01DATA;
  hspi4.Init.TxCRCInitializationPattern = SPI_CRC_INITIALIZATION_ALL_ZERO_PATTERN;
  hspi4.Init.RxCRCInitializationPattern = SPI_CRC_INITIALIZATION_ALL_ZERO_PATTERN;
  hspi4.Init.MasterSSIdleness = SPI_MASTER_SS_IDLENESS_00CYCLE;
  hspi4.Init.MasterInterDataIdleness = SPI_MASTER_INTERDATA_IDLENESS_00CYCLE;
  hspi4.Init.MasterReceiverAutoSusp = SPI_MASTER_RX_AUTOSUSP_DISABLE;
  hspi4.Init.MasterKeepIOState = SPI_MASTER_KEEP_IO_STATE_DISABLE;
  hspi4.Init.IOSwap = SPI_IO_SWAP_DISABLE;
  if (HAL_SPI_Init(&hspi4) != HAL_OK)
  {
    Error_Handler();
  }

}

static void MX_TIM6_Init(void)
{

  TIM_MasterConfigTypeDef sMasterConfig = {0};

  htim6.Instance = TIM6;
  htim6.Init.Prescaler = 120;
  htim6.Init.CounterMode = TIM_COUNTERMODE_UP;
  htim6.Init.Period = 4000;
  htim6.Init.AutoReloadPreload = TIM_AUTORELOAD_PRELOAD_ENABLE;
  if (HAL_TIM_Base_Init(&htim6) != HAL_OK)
  {
    Error_Handler();
  }
  sMasterConfig.MasterOutputTrigger = TIM_TRGO_UPDATE;
  sMasterConfig.MasterSlaveMode = TIM_MASTERSLAVEMODE_DISABLE;
  if (HAL_TIMEx_MasterConfigSynchronization(&htim6, &sMasterConfig) != HAL_OK)
  {
    Error_Handler();
  }

}

static void MX_TIM7_Init(void)
{

  TIM_MasterConfigTypeDef sMasterConfig = {0};

  htim7.Instance = TIM7;
  htim7.Init.Prescaler = 9600;
  htim7.Init.CounterMode = TIM_COUNTERMODE_UP;
  htim7.Init.Period = 1000;
  htim7.Init.AutoReloadPreload = TIM_AUTORELOAD_PRELOAD_ENABLE;
  if (HAL_TIM_Base_Init(&htim7) != HAL_OK)
  {
    Error_Handler();
  }
  sMasterConfig.MasterOutputTrigger = TIM_TRGO_UPDATE;
  sMasterConfig.MasterSlaveMode = TIM_MASTERSLAVEMODE_DISABLE;
  if (HAL_TIMEx_MasterConfigSynchronization(&htim7, &sMasterConfig) != HAL_OK)
  {
    Error_Handler();
  }

}

static void MX_TIM15_Init(void)
{

  TIM_ClockConfigTypeDef sClockSourceConfig = {0};
  TIM_MasterConfigTypeDef sMasterConfig = {0};

  htim15.Instance = TIM15;
  htim15.Init.Prescaler = 48000;
  htim15.Init.CounterMode = TIM_COUNTERMODE_UP;
  htim15.Init.Period = 1000;
  htim15.Init.ClockDivision = TIM_CLOCKDIVISION_DIV1;
  htim15.Init.RepetitionCounter = 0;
  htim15.Init.AutoReloadPreload = TIM_AUTORELOAD_PRELOAD_ENABLE;
  if (HAL_TIM_Base_Init(&htim15) != HAL_OK)
  {
    Error_Handler();
  }
  sClockSourceConfig.ClockSource = TIM_CLOCKSOURCE_INTERNAL;
  if (HAL_TIM_ConfigClockSource(&htim15, &sClockSourceConfig) != HAL_OK)
  {
    Error_Handler();
  }
  sMasterConfig.MasterOutputTrigger = TIM_TRGO_UPDATE;
  sMasterConfig.MasterSlaveMode = TIM_MASTERSLAVEMODE_DISABLE;
  if (HAL_TIMEx_MasterConfigSynchronization(&htim15, &sMasterConfig) != HAL_OK)
  {
    Error_Handler();
  }

}

static void MX_UART5_Init(void)
{

  huart5.Instance = UART5;
  huart5.Init.BaudRate = 9600;
  huart5.Init.WordLength = UART_WORDLENGTH_8B;
  huart5.Init.StopBits = UART_STOPBITS_1;
  huart5.Init.Parity = UART_PARITY_NONE;
  huart5.Init.Mode = UART_MODE_TX_RX;
  huart5.Init.HwFlowCtl = UART_HWCONTROL_NONE;
  huart5.Init.OverSampling = UART_OVERSAMPLING_16;
  huart5.Init.OneBitSampling = UART_ONE_BIT_SAMPLE_DISABLE;
  huart5.Init.ClockPrescaler = UART_PRESCALER_DIV1;
  huart5.AdvancedInit.AdvFeatureInit = UART_ADVFEATURE_NO_INIT;
  if (HAL_UART_Init(&huart5) != HAL_OK)
  {
    Error_Handler();
  }
  if (HAL_UARTEx_SetTxFifoThreshold(&huart5, UART_TXFIFO_THRESHOLD_1_8) != HAL_OK)
  {
    Error_Handler();
  }
  if (HAL_UARTEx_SetRxFifoThreshold(&huart5, UART_RXFIFO_THRESHOLD_1_8) != HAL_OK)
  {
    Error_Handler();
  }
  if (HAL_UARTEx_DisableFifoMode(&huart5) != HAL_OK)
  {
    Error_Handler();
  }

}

static void MX_USART3_UART_Init(void)
{

  huart3.Instance = USART3;
  huart3.Init.BaudRate = 115200;
  huart3.Init.WordLength = UART_WORDLENGTH_8B;
  huart3.Init.StopBits = UART_STOPBITS_1;
  huart3.Init.Parity = UART_PARITY_NONE;
  huart3.Init.Mode = UART_MODE_TX_RX;
  huart3.Init.HwFlowCtl = UART_HWCONTROL_NONE;
  huart3.Init.OverSampling = UART_OVERSAMPLING_16;
  huart3.Init.OneBitSampling = UART_ONE_BIT_SAMPLE_DISABLE;
  huart3.Init.ClockPrescaler = UART_PRESCALER_DIV1;
  huart3.AdvancedInit.AdvFeatureInit = UART_ADVFEATURE_NO_INIT;
  if (HAL_UART_Init(&huart3) != HAL_OK)
  {
    Error_Handler();
  }
  if (HAL_UARTEx_SetTxFifoThreshold(&huart3, UART_TXFIFO_THRESHOLD_1_8) != HAL_OK)
  {
    Error_Handler();
  }
  if (HAL_UARTEx_SetRxFifoThreshold(&huart3, UART_RXFIFO_THRESHOLD_1_8) != HAL_OK)
  {
    Error_Handler();
  }
  if (HAL_UARTEx_DisableFifoMode(&huart3) != HAL_OK)
  {
    Error_Handler();
  }

}

static void MX_USART6_UART_Init(void)
{

  huart6.Instance = USART6;
  huart6.Init.BaudRate = 115200;
  huart6.Init.WordLength = UART_WORDLENGTH_8B;
  huart6.Init.StopBits = UART_STOPBITS_1;
  huart6.Init.Parity = UART_PARITY_NONE;
  huart6.Init.Mode = UART_MODE_TX_RX;
  huart6.Init.HwFlowCtl = UART_HWCONTROL_NONE;
  huart6.Init.OverSampling = UART_OVERSAMPLING_16;
  huart6.Init.OneBitSampling = UART_ONE_BIT_SAMPLE_DISABLE;
  huart6.Init.ClockPrescaler = UART_PRESCALER_DIV1;
  huart6.AdvancedInit.AdvFeatureInit = UART_ADVFEATURE_NO_INIT;
  if (HAL_UART_Init(&huart6) != HAL_OK)
  {
    Error_Handler();
  }
  if (HAL_UARTEx_SetTxFifoThreshold(&huart6, UART_TXFIFO_THRESHOLD_1_8) != HAL_OK)
  {
    Error_Handler();
  }
  if (HAL_UARTEx_SetRxFifoThreshold(&huart6, UART_RXFIFO_THRESHOLD_1_8) != HAL_OK)
  {
    Error_Handler();
  }
  if (HAL_UARTEx_DisableFifoMode(&huart6) != HAL_OK)
  {
    Error_Handler();
  }

}

static void MX_GPIO_Init(void)
{
  GPIO_InitTypeDef GPIO_InitStruct = {0};

  /* GPIO Ports Clock Enable */
  __HAL_RCC_GPIOE_CLK_ENABLE();
  __HAL_RCC_GPIOC_CLK_ENABLE();
  __HAL_RCC_GPIOF_CLK_ENABLE();
  __HAL_RCC_GPIOH_CLK_ENABLE();
  __HAL_RCC_GPIOA_CLK_ENABLE();
  __HAL_RCC_GPIOB_CLK_ENABLE();
  __HAL_RCC_GPIOD_CLK_ENABLE();
  __HAL_RCC_GPIOG_CLK_ENABLE();

  /*Configure GPIO pin Output Level */
  HAL_GPIO_WritePin(GPIOE, LCD_DC_Pin|SegE_Pin|SegF_Pin|Buzzer_Pin
                          |SegA_Pin|SegS0_Pin|SegC_Pin|LD2_Pin, GPIO_PIN_RESET);

  /*Configure GPIO pin Output Level */
  HAL_GPIO_WritePin(W25_NSS_GPIO_Port, W25_NSS_Pin, GPIO_PIN_SET);

  /*Configure GPIO pin Output Level */
  HAL_GPIO_WritePin(GPIOF, SegS2_Pin|SegH_Pin, GPIO_PIN_RESET);

  /*Configure GPIO pin Output Level */
  HAL_GPIO_WritePin(LCD_RST_GPIO_Port, LCD_RST_Pin, GPIO_PIN_RESET);

  /*Configure GPIO pin Output Level */
  HAL_GPIO_WritePin(SegB_GPIO_Port, SegB_Pin, GPIO_PIN_RESET);

  /*Configure GPIO pin Output Level */
  HAL_GPIO_WritePin(GPIOB, LD1_Pin|ESP_EN_Pin|LD3_Pin|LCD_CS_Pin, GPIO_PIN_RESET);

  /*Configure GPIO pin Output Level */
  HAL_GPIO_WritePin(GPIOD, USB_OTG_FS_PWR_EN_Pin|SegS1_Pin|LCD_CTRL_Pin, GPIO_PIN_RESET);

  /*Configure GPIO pin Output Level */
  HAL_GPIO_WritePin(GPIOG, SegG_Pin|SegS3_Pin|SegD_Pin, GPIO_PIN_RESET);

  /*Configure GPIO pin : LCD_DC_Pin */
  GPIO_InitStruct.Pin = LCD_DC_Pin;
  GPIO_InitStruct.Mode = GPIO_MODE_OUTPUT_PP;
  GPIO_InitStruct.Pull = GPIO_NOPULL;
  GPIO_InitStruct.Speed = GPIO_SPEED_FREQ_HIGH;
  HAL_GPIO_Init(LCD_DC_GPIO_Port, &GPIO_InitStruct);

  /*Configure GPIO pin : W25_NSS_Pin */
  GPIO_InitStruct.Pin = W25_NSS_Pin;
  GPIO_InitStruct.Mode = GPIO_MODE_OUTPUT_PP;
  GPIO_InitStruct.Pull = GPIO_PULLUP;
  GPIO_InitStruct.Speed = GPIO_SPEED_FREQ_HIGH;
  HAL_GPIO_Init(W25_NSS_GPIO_Port, &GPIO_InitStruct);

  /*Configure GPIO pin : B1_Pin */
  GPIO_InitStruct.Pin = B1_Pin;
  GPIO_InitStruct.Mode = GPIO_MODE_IT_RISING;
  GPIO_InitStruct.Pull = GPIO_NOPULL;
  HAL_GPIO_Init(B1_GPIO_Port, &GPIO_InitStruct);

  /*Configure GPIO pin : SDMMC1_CD_Pin */
  GPIO_InitStruct.Pin = SDMMC1_CD_Pin;
  GPIO_InitStruct.Mode = GPIO_MODE_INPUT;
  GPIO_InitStruct.Pull = GPIO_NOPULL;
  HAL_GPIO_Init(SDMMC1_CD_GPIO_Port, &GPIO_InitStruct);

  /*Configure GPIO pins : SegS2_Pin SegH_Pin */
  GPIO_InitStruct.Pin = SegS2_Pin|SegH_Pin;
  GPIO_InitStruct.Mode = GPIO_MODE_OUTPUT_PP;
  GPIO_InitStruct.Pull = GPIO_NOPULL;
  GPIO_InitStruct.Speed = GPIO_SPEED_FREQ_LOW;
  HAL_GPIO_Init(GPIOF, &GPIO_InitStruct);

  /*Configure GPIO pin : LCD_RST_Pin */
  GPIO_InitStruct.Pin = LCD_RST_Pin;
  GPIO_InitStruct.Mode = GPIO_MODE_OUTPUT_PP;
  GPIO_InitStruct.Pull = GPIO_NOPULL;
  GPIO_InitStruct.Speed = GPIO_SPEED_FREQ_LOW;
  HAL_GPIO_Init(LCD_RST_GPIO_Port, &GPIO_InitStruct);

  /*Configure GPIO pin : SegB_Pin */
  GPIO_InitStruct.Pin = SegB_Pin;
  GPIO_InitStruct.Mode = GPIO_MODE_OUTPUT_PP;
  GPIO_InitStruct.Pull = GPIO_NOPULL;
  GPIO_InitStruct.Speed = GPIO_SPEED_FREQ_LOW;
  HAL_GPIO_Init(SegB_GPIO_Port, &GPIO_InitStruct);

  /*Configure GPIO pin : PA5 */
  GPIO_InitStruct.Pin = GPIO_PIN_5;
  GPIO_InitStruct.Mode = GPIO_MODE_INPUT;
  GPIO_InitStruct.Pull = GPIO_NOPULL;
  HAL_GPIO_Init(GPIOA, &GPIO_InitStruct);

  /*Configure GPIO pins : LD1_Pin ESP_EN_Pin LD3_Pin */
  GPIO_InitStruct.Pin = LD1_Pin|ESP_EN_Pin|LD3_Pin;
  GPIO_InitStruct.Mode = GPIO_MODE_OUTPUT_PP;
  GPIO_InitStruct.Pull = GPIO_NOPULL;
  GPIO_InitStruct.Speed = GPIO_SPEED_FREQ_LOW;
  HAL_GPIO_Init(GPIOB, &GPIO_InitStruct);

  /*Configure GPIO pins : exB0_Pin exB1_Pin RoteryA_Pin RoteryB_Pin
                           RoteryBtn_Pin */
  GPIO_InitStruct.Pin = exB0_Pin|exB1_Pin|RoteryA_Pin|RoteryB_Pin
                          |RoteryBtn_Pin;
  GPIO_InitStruct.Mode = GPIO_MODE_IT_RISING;
  GPIO_InitStruct.Pull = GPIO_NOPULL;
  HAL_GPIO_Init(GPIOB, &GPIO_InitStruct);

  /*Configure GPIO pins : SegE_Pin SegF_Pin Buzzer_Pin SegA_Pin
                           SegS0_Pin SegC_Pin LD2_Pin */
  GPIO_InitStruct.Pin = SegE_Pin|SegF_Pin|Buzzer_Pin|SegA_Pin
                          |SegS0_Pin|SegC_Pin|LD2_Pin;
  GPIO_InitStruct.Mode = GPIO_MODE_OUTPUT_PP;
  GPIO_InitStruct.Pull = GPIO_NOPULL;
  GPIO_InitStruct.Speed = GPIO_SPEED_FREQ_LOW;
  HAL_GPIO_Init(GPIOE, &GPIO_InitStruct);

  /*Configure GPIO pins : USB_OTG_FS_PWR_EN_Pin SegS1_Pin LCD_CTRL_Pin */
  GPIO_InitStruct.Pin = USB_OTG_FS_PWR_EN_Pin|SegS1_Pin|LCD_CTRL_Pin;
  GPIO_InitStruct.Mode = GPIO_MODE_OUTPUT_PP;
  GPIO_InitStruct.Pull = GPIO_NOPULL;
  GPIO_InitStruct.Speed = GPIO_SPEED_FREQ_LOW;
  HAL_GPIO_Init(GPIOD, &GPIO_InitStruct);

  /*Configure GPIO pins : SegG_Pin SegS3_Pin SegD_Pin */
  GPIO_InitStruct.Pin = SegG_Pin|SegS3_Pin|SegD_Pin;
  GPIO_InitStruct.Mode = GPIO_MODE_OUTPUT_PP;
  GPIO_InitStruct.Pull = GPIO_NOPULL;
  GPIO_InitStruct.Speed = GPIO_SPEED_FREQ_LOW;
  HAL_GPIO_Init(GPIOG, &GPIO_InitStruct);

  /*Configure GPIO pin : USB_OTG_FS_OVCR_Pin */
  GPIO_InitStruct.Pin = USB_OTG_FS_OVCR_Pin;
  GPIO_InitStruct.Mode = GPIO_MODE_IT_RISING;
  GPIO_InitStruct.Pull = GPIO_NOPULL;
  HAL_GPIO_Init(USB_OTG_FS_OVCR_GPIO_Port, &GPIO_InitStruct);

  /*Configure GPIO pin : LCD_CS_Pin */
  GPIO_InitStruct.Pin = LCD_CS_Pin;
  GPIO_InitStruct.Mode = GPIO_MODE_OUTPUT_PP;
  GPIO_InitStruct.Pull = GPIO_NOPULL;
  GPIO_InitStruct.Speed = GPIO_SPEED_FREQ_HIGH;
  HAL_GPIO_Init(LCD_CS_GPIO_Port, &GPIO_InitStruct);

  /* EXTI interrupt init*/
  HAL_NVIC_SetPriority(EXTI1_IRQn, 0, 0);
  HAL_NVIC_EnableIRQ(EXTI1_IRQn);

  HAL_NVIC_SetPriority(EXTI2_IRQn, 0, 0);
  HAL_NVIC_EnableIRQ(EXTI2_IRQn);

  HAL_NVIC_SetPriority(EXTI9_5_IRQn, 0, 0);
  HAL_NVIC_EnableIRQ(EXTI9_5_IRQn);

  HAL_NVIC_SetPriority(EXTI15_10_IRQn, 0, 0);
  HAL_NVIC_EnableIRQ(EXTI15_10_IRQn);

}

/* USER CODE BEGIN 4 */
void invoke_case(const char *case_name, bool (*fn)()) {
	text_panel_print("%s test...", case_name);
	if (fn())
		text_panel_print("OK\n");
	else
		text_panel_print("Fail\n");
}

void HAL_TIM_PeriodElapsedCallback(TIM_HandleTypeDef *htim) {
	if (htim->Instance == htim6.Instance)
		segment_flush(seg_handle);
	if (htim->Instance == htim7.Instance) {
		MX_LWIP_Process();
	}
}

void HAL_ADC_ConvCpltCallback(ADC_HandleTypeDef *hadc) {
	uint32_t adc_value = HAL_ADC_GetValue(&hadc2);
	int v = adc_value * 3300 / 65535;
	segment_float_set(seg_handle, v / 1000, v % 1000, 3);
	HAL_DAC_SetValue(&hdac1, DAC_CHANNEL_1, DAC_ALIGN_12B_R, adc_value >> 4);
	HAL_DAC_Start(&hdac1, DAC_CHANNEL_1);
}

void touch_event() {
	if (LCD_Touch_is_Touching()) {
		LCD_Touch_Get_Position(&x, &y);

		/* Set all bytes buf as 0xFF to create white line */
		memset(buf, 0x00, 640);
		SSD1289_set_window(lcd, last_x, 0, 1, 320);
		SSD1289_transmit_to_ram(lcd, buf, 640);
		SSD1289_set_window(lcd, 0, last_y, 240, 1);
		SSD1289_transmit_to_ram(lcd, buf, 480);

		/* Set all bytes buf as 0x00 to create black line */
		memset(buf, 0xFF, 640);
		SSD1289_set_window(lcd, x, 0, 1, 320);
		SSD1289_transmit_to_ram(lcd, buf, 640);
		SSD1289_set_window(lcd, 0, y, 240, 1);
		SSD1289_transmit_to_ram(lcd, buf, 480);

		last_x = x;
		last_y = y;

		while (LCD_Touch_is_Touching())
			;
	}
}

static void FDCAN_Config(void) {
	FDCAN_FilterTypeDef sFilterConfig;

	/* Configure Rx filter */
	sFilterConfig.IdType = FDCAN_STANDARD_ID;
	sFilterConfig.FilterIndex = 0;
//sFilterConfig.FilterType = FDCAN_FILTER_MASK;
	sFilterConfig.FilterConfig = FDCAN_FILTER_TO_RXBUFFER;
	sFilterConfig.FilterID1 = 0x01;
	sFilterConfig.RxBufferIndex = 0;
//sFilterConfig.FilterID2 = 0x7FF;
	if (HAL_FDCAN_ConfigFilter(&hfdcan1, &sFilterConfig) != HAL_OK) {
		/* Filter configuration Error */
		Error_Handler();
	}
	/* Prepare Tx Header */
	TxHeader.Identifier = 0x321;
	TxHeader.IdType = FDCAN_STANDARD_ID;
	TxHeader.TxFrameType = FDCAN_DATA_FRAME;
	TxHeader.DataLength = FDCAN_DLC_BYTES_2;
	TxHeader.ErrorStateIndicator = FDCAN_ESI_ACTIVE;
	TxHeader.BitRateSwitch = FDCAN_BRS_ON;
	TxHeader.FDFormat = FDCAN_FD_CAN;
	TxHeader.TxEventFifoControl = FDCAN_NO_TX_EVENTS;
	TxHeader.MessageMarker = 0; //ignore because FDCAN_NO_TX_EVENTS

	/* Start the FDCAN module */
	if (HAL_FDCAN_Start(&hfdcan1) != HAL_OK) {
		/* Start Error */
		Error_Handler();
	}
	HAL_FDCAN_ActivateNotification(&hfdcan1, FDCAN_IT_RX_FIFO0_NEW_MESSAGE, 0);
}

void HAL_FDCAN_RxFifo0Callback(FDCAN_HandleTypeDef *hfdcan, uint32_t RxFifo0ITs) {
	if ((RxFifo0ITs & FDCAN_IT_RX_FIFO0_NEW_MESSAGE) != RESET) {
		/* Retreive Rx messages from RX FIFO0 */
		if (HAL_FDCAN_GetRxMessage(hfdcan, FDCAN_RX_FIFO0, &RxHeader, RxData)
				!= HAL_OK) {
			/* Reception Error */
			Error_Handler();
		}

		/* Display LEDx */

		if (HAL_FDCAN_ActivateNotification(hfdcan,
		FDCAN_IT_RX_FIFO0_NEW_MESSAGE, 0) != HAL_OK) {
			/* Notification Error */
			Error_Handler();
		}
	}
}

/* USER CODE END 4 */

 /* MPU Configuration */

void MPU_Config(void)
{
  MPU_Region_InitTypeDef MPU_InitStruct = {0};

  /* Disables the MPU */
  HAL_MPU_Disable();

  /** Initializes and configures the Region and the memory to be protected
  */
  MPU_InitStruct.Enable = MPU_REGION_ENABLE;
  MPU_InitStruct.Number = MPU_REGION_NUMBER0;
  MPU_InitStruct.BaseAddress = 0x30020000;
  MPU_InitStruct.Size = MPU_REGION_SIZE_128KB;
  MPU_InitStruct.SubRegionDisable = 0x0;
  MPU_InitStruct.TypeExtField = MPU_TEX_LEVEL1;
  MPU_InitStruct.AccessPermission = MPU_REGION_FULL_ACCESS;
  MPU_InitStruct.DisableExec = MPU_INSTRUCTION_ACCESS_DISABLE;
  MPU_InitStruct.IsShareable = MPU_ACCESS_NOT_SHAREABLE;
  MPU_InitStruct.IsCacheable = MPU_ACCESS_NOT_CACHEABLE;
  MPU_InitStruct.IsBufferable = MPU_ACCESS_NOT_BUFFERABLE;

  HAL_MPU_ConfigRegion(&MPU_InitStruct);

  /** Initializes and configures the Region and the memory to be protected
  */
  MPU_InitStruct.Number = MPU_REGION_NUMBER1;
  MPU_InitStruct.BaseAddress = 0x30040000;
  MPU_InitStruct.Size = MPU_REGION_SIZE_512B;
  MPU_InitStruct.TypeExtField = MPU_TEX_LEVEL0;
  MPU_InitStruct.IsShareable = MPU_ACCESS_SHAREABLE;
  MPU_InitStruct.IsBufferable = MPU_ACCESS_BUFFERABLE;

  HAL_MPU_ConfigRegion(&MPU_InitStruct);
  /* Enables the MPU */
  HAL_MPU_Enable(MPU_PRIVILEGED_DEFAULT);

}

void Error_Handler(void)
{
	__disable_irq();
	while (1) {
	}
}
